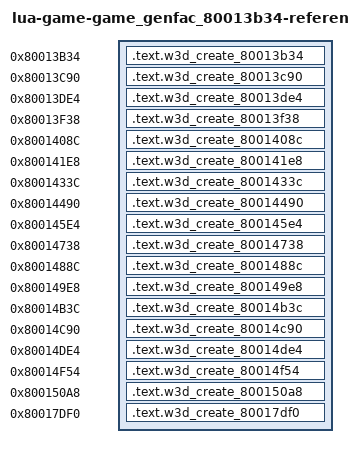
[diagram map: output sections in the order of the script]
/* Generated reference-only placements. All bodies are source-built. */
OUTPUT_FORMAT("elf32-powerpc")
OUTPUT_ARCH(powerpc)
ENTRY(w3d_create_80013b34)
_SDA_BASE_ = 0x804b2540;
_SDA2_BASE_ = 0x804c2540;
__18w3d_class_80013b6ci = 0x80013b6c;
__18w3d_class_80013cc8i = 0x80013cc8;
__18w3d_class_80013e1ci = 0x80013e1c;
__18w3d_class_80013f70i = 0x80013f70;
__18w3d_class_800140c4i = 0x800140c4;
__18w3d_class_80014220i = 0x80014220;
__18w3d_class_80014374i = 0x80014374;
__18w3d_class_800144c8i = 0x800144c8;
__18w3d_class_8001461ci = 0x8001461c;
__18w3d_class_80014770i = 0x80014770;
__18w3d_class_800148c4i = 0x800148c4;
__18w3d_class_80014a20i = 0x80014a20;
__18w3d_class_80014b74i = 0x80014b74;
__18w3d_class_80014cc8i = 0x80014cc8;
__18w3d_class_80014e1ci = 0x80014e1c;
__18w3d_class_80014f8ci = 0x80014f8c;
__18w3d_class_800150e0i = 0x800150e0;
__18w3d_class_80017e28i = 0x80017e28;
__builtin_new = 0x8001523c;
SECTIONS {
  .text.w3d_create_80013b34 0x80013b34 : { *(.text.w3d_create_80013b34) }
  .text.w3d_create_80013c90 0x80013c90 : { *(.text.w3d_create_80013c90) }
  .text.w3d_create_80013de4 0x80013de4 : { *(.text.w3d_create_80013de4) }
  .text.w3d_create_80013f38 0x80013f38 : { *(.text.w3d_create_80013f38) }
  .text.w3d_create_8001408c 0x8001408c : { *(.text.w3d_create_8001408c) }
  .text.w3d_create_800141e8 0x800141e8 : { *(.text.w3d_create_800141e8) }
  .text.w3d_create_8001433c 0x8001433c : { *(.text.w3d_create_8001433c) }
  .text.w3d_create_80014490 0x80014490 : { *(.text.w3d_create_80014490) }
  .text.w3d_create_800145e4 0x800145e4 : { *(.text.w3d_create_800145e4) }
  .text.w3d_create_80014738 0x80014738 : { *(.text.w3d_create_80014738) }
  .text.w3d_create_8001488c 0x8001488c : { *(.text.w3d_create_8001488c) }
  .text.w3d_create_800149e8 0x800149e8 : { *(.text.w3d_create_800149e8) }
  .text.w3d_create_80014b3c 0x80014b3c : { *(.text.w3d_create_80014b3c) }
  .text.w3d_create_80014c90 0x80014c90 : { *(.text.w3d_create_80014c90) }
  .text.w3d_create_80014de4 0x80014de4 : { *(.text.w3d_create_80014de4) }
  .text.w3d_create_80014f54 0x80014f54 : { *(.text.w3d_create_80014f54) }
  .text.w3d_create_800150a8 0x800150a8 : { *(.text.w3d_create_800150a8) }
  .text.w3d_create_80017df0 0x80017df0 : { *(.text.w3d_create_80017df0) }
  /DISCARD/ : { *(.text*) *(.rodata*) *(.data*) *(.bss*) *(.sdata*) *(.sbss*) *(.comment) }
}
